# ATmega168PB register map
Vendor: Atmel; File version: 1.0
CPU: other r0p0, little endian, no MPU, no FPU, 4 interrupt priority bits
Registers are 8-bit, read-write, reset 0x0 unless marked. A register's access mark holds for its fields unless they carry their own. Offsets are from the block's base; lines under a group give offsets from that group; [hi:lo] are bit positions; {n}, {i} and the like mark numbered series; 'fields as' and 'values as' point back to an identical list; <NAME> marks a mode.

## Memory map
0x00000000 FUSE size 0x3 — Fuses
0x00000000 LOCKBIT size 0x1 — Lockbits
0x00000023 PORTB size 0x3 — I/O Port
0x00000026 PORTC size 0x3 — I/O Port
0x00000029 PORTD size 0x3 — I/O Port
0x0000002C PORTE size 0x3 — I/O Port
0x00000035 TC0 blocks up to offset 0x3A — Timer/Counter, 8-bit
0x00000036 TC1 blocks up to offset 0x56 — Timer/Counter, 16-bit
0x00000037 TC2 blocks up to offset 0x80 — Timer/Counter, 8-bit Async
0x0000003B EXINT blocks up to offset 0x33 — External Interrupts
0x0000003E CPU blocks up to offset 0x29 — CPU Registers
0x0000003F EEPROM size 0x4
0x0000004C SPI size 0x3 — Serial Peripheral Interface
0x0000004F AC blocks up to offset 0x31 — Analog Comparator
0x00000060 WDT size 0x1 — Watchdog Timer
0x00000078 ADC blocks up to offset 0x7 — Analog-to-Digital Converter
0x000000B8 TWI size 0x6 — Two Wire Serial Interface
0x000000C0 USART0 size 0x7 — USART
0x000000F0 DEVICEID size 0x9

## Interrupts
0 RESET (CPU) — External Pin, Power-on Reset, Brown-out Reset and Watchdog Reset
1 INT0 (CPU) — External Interrupt Request 0
2 INT1 (CPU) — External Interrupt Request 1
3 PCINT0 (CPU) — Pin Change Interrupt Request 0
4 PCINT1 (CPU) — Pin Change Interrupt Request 0
5 PCINT2 (CPU) — Pin Change Interrupt Request 1
6 WDT (CPU) — Watchdog Time-out Interrupt
7 TIMER2_COMPA (CPU) — Timer/Counter2 Compare Match A
8 TIMER2_COMPB (CPU) — Timer/Counter2 Compare Match A
9 TIMER2_OVF (CPU) — Timer/Counter2 Overflow
10 TIMER1_CAPT (CPU) — Timer/Counter1 Capture Event
11 TIMER1_COMPA (CPU) — Timer/Counter1 Compare Match A
12 TIMER1_COMPB (CPU) — Timer/Counter1 Compare Match B
13 TIMER1_OVF (CPU) — Timer/Counter1 Overflow
14 TIMER0_COMPA (CPU) — TimerCounter0 Compare Match A
15 TIMER0_COMPB (CPU) — TimerCounter0 Compare Match B
16 TIMER0_OVF (CPU) — Timer/Couner0 Overflow
17 SPI_STC (CPU) — SPI Serial Transfer Complete
18 USART_RX (CPU) — USART Rx Complete
19 USART_UDRE (CPU) — USART, Data Register Empty
20 USART_TX (CPU) — USART Tx Complete
21 ADC (CPU) — ADC Conversion Complete
22 EE_READY (CPU) — EEPROM Ready
23 ANALOG_COMP (CPU) — Analog Comparator
24 TWI (CPU) — Two-wire Serial Interface
25 SPM_Ready (CPU) — Store Program Memory Read
26 USART_START (CPU) — USART Start Edge Interrupt

## AC — Analog Comparator
Base 0x0000004F
0x00 ACSRB — Analog Comparator Status Register B
  [0] ACOE — Analog Comparator Output Enable
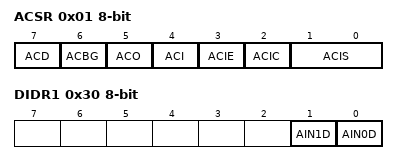
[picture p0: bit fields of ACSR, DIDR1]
0x01 ACSR — Analog Comparator Control And Status Register
  [7] ACD — Analog Comparator Disable
  [6] ACBG — Analog Comparator Bandgap Select
  [5] ACO — Analog Compare Output
  [4] ACI — Analog Comparator Interrupt Flag
  [3] ACIE — Analog Comparator Interrupt Enable
  [2] ACIC — Analog Comparator Input Capture Enable
  [1:0] ACIS — Analog Comparator Interrupt Mode Select bits
    0=Interrupt on Toggle; 2=Interrupt on Falling Edge; 3=Interrupt on Rising Edge
0x30 DIDR1 — Digital Input Disable Register 1
  [1] AIN1D — AIN1 Digital Input Disable
  [0] AIN0D — AIN0 Digital Input Disable

## ADC — Analog-to-Digital Converter
Base 0x00000078
0x00 ADC 16-bit (reset mask 0xFF) — ADC Data Register Bytes
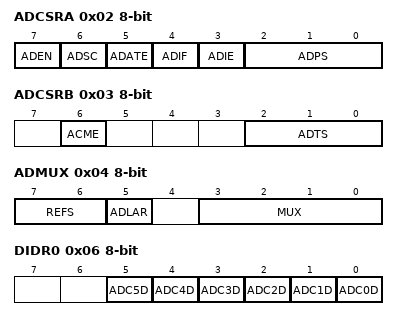
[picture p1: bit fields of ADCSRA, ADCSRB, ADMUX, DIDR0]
0x02 ADCSRA — The ADC Control and Status register A
  [7] ADEN — ADC Enable
  [6] ADSC — ADC Start Conversion
  [5] ADATE — ADC Auto Trigger Enable
  [4] ADIF — ADC Interrupt Flag
  [3] ADIE — ADC Interrupt Enable
  [2:0] ADPS — ADC Prescaler Select Bits
    0=2; 1=2; 2=4; 3=8; 4=16; 5=32; 6=64; 7=128
0x03 ADCSRB — The ADC Control and Status register B
  [6] ACME
  [2:0] ADTS — ADC Auto Trigger Source bits
    0=Free Running mode; 1=Analog Comparator; 2=External Interrupt Request 0; 3=Timer/Counter0 Compare Match A; 4=Timer/Counter0 Overflow; 5=Timer/Counter1 Compare Match B; 6=Timer/Counter1 Overflow; 7=Timer/Counter1 Capture Event
0x04 ADMUX — The ADC multiplexer Selection Register
  [7:6] REFS — Reference Selection Bits
    0=AREF, Internal Vref turned off; 1=AVCC with external capacitor at AREF pin; 3=Internal 1.1V Voltage Reference with external capacitor at AREF pin
  [5] ADLAR — Left Adjust Result
  [3:0] MUX — Analog Channel Selection Bits
    {v}=ADC{v} (ADC Single Ended Input pin {v}) (v=0..7); 8=TEMPSENS (Temperature sensor); 14=ADC_VBG (Internal Reference (VBG)); 15=ADC_GND (0V (GND))
0x06 DIDR0 — Digital Input Disable Register
  [n] ADC{n}D (n=0..5)
